# STM32G0C1 register map
File version: 1.8
CPU: CM0 r0p1, little endian, MPU, no FPU, 2 interrupt priority bits
Registers are 32-bit, read-write, reset 0x0 unless marked. A register's access mark holds for its fields unless they carry their own. Offsets are from the block's base; [hi:lo] are bit positions.

## CRC — Cyclic redundancy check calculation unit
Base 0x40023000
0x00 DR reset 0xFFFFFFFF — Data register
  [31:0] DR — Data register bits
0x00 DR8 8-bit reset 0xFF (alternate view of DR) — Data register - byte sized
  [7:0] DR8 — Data register bits
0x00 DR16 16-bit reset 0xFFFF (alternate view of DR) — Data register - half-word sized
  [15:0] DR16 — Data register bits
0x04 IDR — Independent data register
  [31:0] IDR — General-purpose 32-bit data register bits
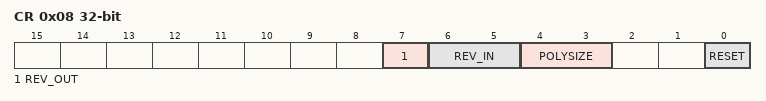
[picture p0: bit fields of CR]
0x08 CR access per field — Control register
  [7] REV_OUT rw — Reverse output data This bit controls the reversal of the bit order of the output data.
    0=Normal (Bit order not affected); 1=Reversed (Bit reversed output)
  [6:5] REV_IN rw — Reverse input data These bits control the reversal of the bit order of the input data
    0=Normal (Bit order not affected); 1=Byte (Bit reversal done by byte); 2=HalfWord (Bit reversal done by half-word); 3=Word (Bit reversal done by word)
  [4:3] POLYSIZE rw — Polynomial size These bits control the size of the polynomial.
    0=32-bit polynomial; 1=16-bit polynomial; 2=8-bit polynomial; 3=7-bit polynomial
  [0] RESET wo — RESET bit
    1=Resets the CRC calculation unit and sets the data register to 0xFFFF FFFF
0x10 INIT reset 0xFFFFFFFF — Initial CRC value
  [31:0] INIT — Programmable initial CRC value
0x14 POL reset 0x4C11DB7 — polynomial
  [31:0] POL — Programmable polynomial

## DBG — Debug support
Base 0x40015800
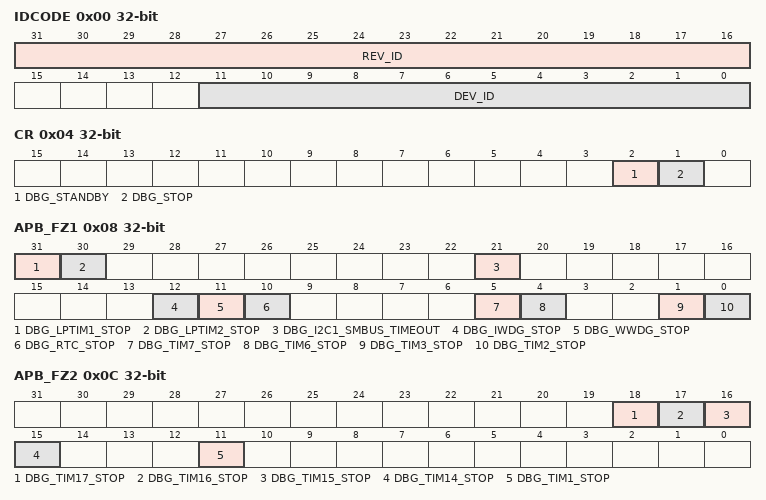
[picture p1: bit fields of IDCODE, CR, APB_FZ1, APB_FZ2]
0x00 IDCODE ro — MCU Device ID Code Register
  [31:16] REV_ID — Revision Identifier
  [11:0] DEV_ID — Device Identifier
0x04 CR — DBG configuration register
  [2] DBG_STANDBY — Debug Standby and Shutdown modes Debug options in Standby or Shutdown mode.
  [1] DBG_STOP — Debug Stop mode Debug options in Stop mode. Upon Stop mode exit, the software must re-establish the desired clock configuration.
0x08 APB_FZ1 — DBG APB freeze register 1
  [31] DBG_LPTIM1_STOP — Clocking of LPTIMER1 counter when the core is halted This bit enables/disables the clock to the counter of LPTIMER1 when the core is halted:
  [30] DBG_LPTIM2_STOP — Clocking of LPTIMER2 counter when the core is halted This bit enables/disables the clock to the counter of LPTIMER2 when the core is halted:
  [21] DBG_I2C1_SMBUS_TIMEOUT — SMBUS timeout when core is halted
  [12] DBG_IWDG_STOP — Clocking of IWDG counter when the core is halted This bit enables/disables the clock to the counter of IWDG when the core is halted:
  [11] DBG_WWDG_STOP — Clocking of WWDG counter when the core is halted This bit enables/disables the clock to the counter of WWDG when the core is halted:
  [10] DBG_RTC_STOP — Clocking of RTC counter when the core is halted This bit enables/disables the clock to the counter of RTC when the core is halted:
  [5] DBG_TIM7_STOP — Clocking of TIM7 counter when the core is halted. This bit enables/disables the clock to the counter of ITIM7 when the core is halted:
  [4] DBG_TIM6_STOP — Clocking of TIM6 counter when the core is halted This bit enables/disables the clock to the counter of TIM6 when the core is halted:
  [1] DBG_TIM3_STOP — Clocking of TIM3 counter when the core is halted This bit enables/disables the clock to the counter of TIM3 when the core is halted:
  [0] DBG_TIM2_STOP — Clocking of TIM2 counter when the core is halted This bit enables/disables the clock to the counter of TIM2 when the core is halted:
0x0C APB_FZ2 — DBG APB freeze register 2
  [18] DBG_TIM17_STOP — Clocking of TIM17 counter when the core is halted This bit enables/disables the clock to the counter of TIM17 when the core is halted:
  [17] DBG_TIM16_STOP — Clocking of TIM16 counter when the core is halted This bit enables/disables the clock to the counter of TIM16 when the core is halted:
  [16] DBG_TIM15_STOP — Clocking of TIM15 counter when the core is halted This bit enables/disables the clock to the counter of TIM15 when the core is halted: Only available on STM32G071xx and STM32G081xx, reserved on STM32G031xx and STM32G041xx.
  [15] DBG_TIM14_STOP — Clocking of TIM14 counter when the core is halted This bit enables/disables the clock to the counter of TIM14 when the core is halted:
  [11] DBG_TIM1_STOP — Clocking of TIM1 counter when the core is halted This bit enables/disables the clock to the counter of TIM1 when the core is halted:
